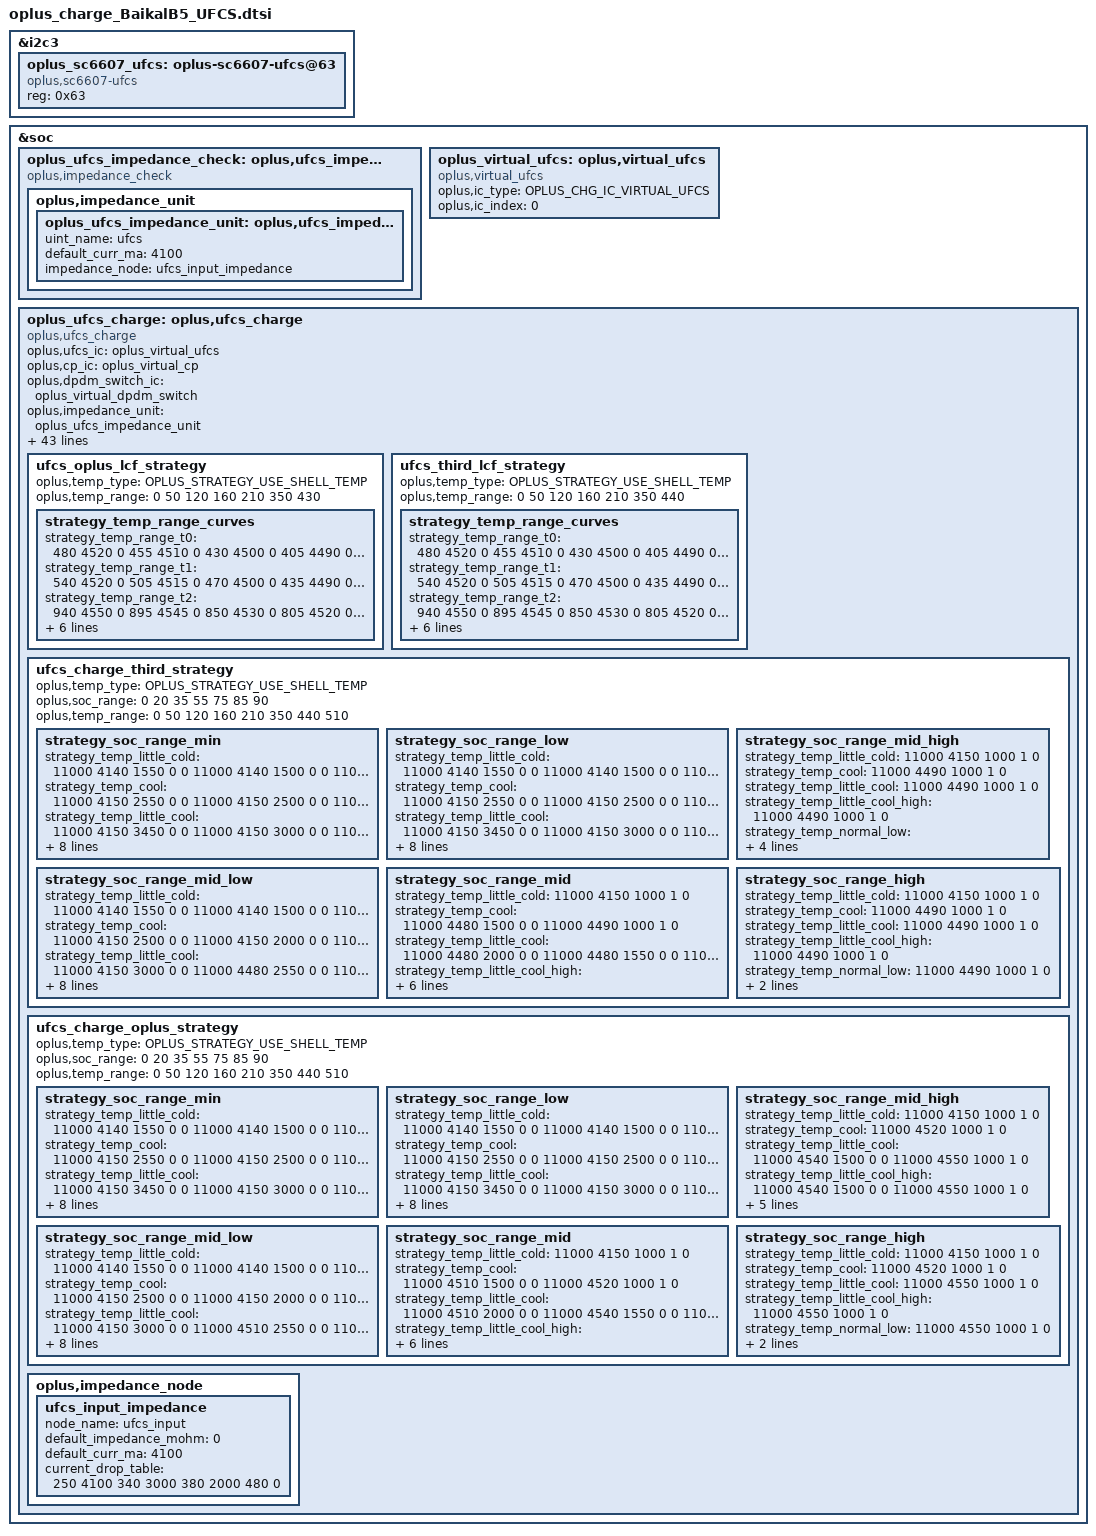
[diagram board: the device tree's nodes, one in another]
&i2c3 {
	oplus_sc6607_ufcs:oplus-sc6607-ufcs@63 {
		status = "okay";
		compatible = "oplus,sc6607-ufcs";
		reg = <0x63>;
	};
};

&soc {
	oplus_ufcs_impedance_check: oplus,ufcs_impedance_check {
		compatible = "oplus,impedance_check";
		oplus,impedance_unit {
			oplus_ufcs_impedance_unit: oplus,ufcs_impedance_unit {
				uint_name = "ufcs";
				default_curr_ma = <4100>;
				impedance_node = <&ufcs_input_impedance>;
			};
		};
	};

	oplus_virtual_ufcs: oplus,virtual_ufcs {
		compatible = "oplus,virtual_ufcs";

		oplus,ic_type = <OPLUS_CHG_IC_VIRTUAL_UFCS>;
		oplus,ic_index = <0>;
	};

	oplus_ufcs_charge: oplus,ufcs_charge {
		compatible = "oplus,ufcs_charge";
		oplus,ufcs_ic = <&oplus_virtual_ufcs>;
		oplus,cp_ic = <&oplus_virtual_cp>;
		oplus,dpdm_switch_ic = <&oplus_virtual_dpdm_switch>;

		oplus,impedance_unit = <&oplus_ufcs_impedance_unit>;

		oplus,plc_strategy-data = <&oplus_ufcs_step_strategy &cp_2t1_simple_strategy>;
		oplus,plc_strategy-names = "default", "third";

		oplus,target_vbus_mv = <11000>;
		oplus,curr_max_ma = <4100>;
		oplus,curr_table_type = <UFCS_CURR_CP_TABLE>;
		oplus,high_imp_compensation_setting_mv = <50>;
		oplus,ufcs_boot_time_retry = <10>;
		oplus,lift_vbus_use_cpvout;
		oplus,subboard_ntc_abnormal_current = <4000>;
		oplus,ufcs_need_reset_adapter;

		oplus,ufcs_warm_allow_vol = <4000>;
		oplus,ufcs_warm_allow_soc = <50>;
		oplus,ufcs_strategy_normal_current = <4000>;
		oplus,ufcs_over_high_or_low_current = <4000>;
		oplus,ufcs_timeout_third = <17562>;
		oplus,ufcs_timeout_oplus = <17562>;
		oplus,ufcs_ibat_over_third = <9400>;
		oplus,ufcs_ibat_over_oplus = <9600>;

		oplus,ufcs_full_cool_sw_vbat = <4520>;
		oplus,ufcs_full_normal_sw_vbat = <4550>;
		oplus,ufcs_full_normal_hw_vbat = <4560>;
		oplus,ufcs_full_ffc_vbat = <4500>;
		oplus,ufcs_full_warm_vbat = <4130>;
		oplus,ufcs_full_cool_sw_vbat_third = <4490>;
		oplus,ufcs_full_normal_sw_vbat_third= <4490>;
		oplus,ufcs_full_normal_hw_vbat_third = <4500>;

		oplus,ufcs_current_change_timeout = <100>;
		oplus,ufcs_strategy_batt_high_temp = <405 420 430 395 410 425>;
		oplus,ufcs_strategy_high_current = <5000 4000 3000 3000 4000 5000>;
		oplus,ufcs_little_cool_high_temp = <200>;
		oplus,curve_strategy_name = "pps_ufcs_curve_v2";
		oplus_spec,ufcs_high_soc = <90>;
		oplus,ufcs_charge_strategy_soc = <0 20 35 50 75 85 90>;
		oplus,ufcs_charge_strategy_temp = <0 50 120 160 350 440 530>;
        oplus,temperature_strategy_name = "cgcl";
        oplus,temperature_strategy_data = <OPLUS_STRATEGY_USE_SHELL_TEMP
                                                0   385 7300 1 0
                                                375 405 5000 2 0
                                                395 420 4000 3 1
                                                410 430 3500 4 2
                                                420 440 2000 4 3>;
		ufcs_oplus_lcf_strategy {
			oplus,temp_type = <OPLUS_STRATEGY_USE_SHELL_TEMP>;
			oplus,temp_range = <0 50 120 160 210 350 430>;

			strategy_temp_range_curves {
				strategy_temp_range_t0 =	<480 4520 0
								 455 4510 0
								 430 4500 0
								 405 4490 0
								 380 4480 1>;
				strategy_temp_range_t1 =	<540 4520 0
								 505 4515 0
								 470 4500 0
								 435 4490 0
								 400 4480 1>;
				strategy_temp_range_t2 =	<940 4550 0
								 895 4545 0
								 850 4530 0
								 805 4520 0
								 760 4510 1>;
				strategy_temp_range_t3 =	<940 4550 0
								 895 4545 0
								 850 4530 0
								 805 4520 0
								 760 4510 1>;
				strategy_temp_range_t4 =	<1780 4550 0
								 1730 4545 0
								 1630 4530 0
								 1530 4520 0
								 1380 4510 1>;
				strategy_temp_range_t5 =	<1910 4550 0
								 1860 4545 0
								 1760 4530 0
								 1660 4520 0
								 1510 4510 1>;
			};
		};

		ufcs_third_lcf_strategy {
			oplus,temp_type = <OPLUS_STRATEGY_USE_SHELL_TEMP>;
			oplus,temp_range = <0 50 120 160 210 350 440>;

			strategy_temp_range_curves {
				strategy_temp_range_t0 =	<480 4520 0
								 455 4510 0
								 430 4500 0
								 405 4490 0
								 380 4480 1>;
				strategy_temp_range_t1 =	<540 4520 0
								 505 4515 0
								 470 4500 0
								 435 4490 0
								 400 4480 1>;
				strategy_temp_range_t2 =	<940 4550 0
								 895 4545 0
								 850 4530 0
								 805 4520 0
								 760 4510 1>;
				strategy_temp_range_t3 =	<940 4550 0
								 895 4545 0
								 850 4530 0
								 805 4520 0
								 760 4510 1>;
				strategy_temp_range_t4 =	<1780 4550 0
								 1730 4545 0
								 1630 4530 0
								 1530 4520 0
								 1380 4510 1>;
				strategy_temp_range_t5 =	<1910 4550 0
								 1860 4545 0
								 1760 4530 0
								 1660 4520 0
								 1510 4510 1>;
			};
		};

		ufcs_charge_third_strategy {
			oplus,temp_type = <OPLUS_STRATEGY_USE_SHELL_TEMP>;
			oplus,soc_range = <0 20 35 55 75 85 90>;
			oplus,temp_range = <0 50 120 160 210 350 440 510>;

			strategy_soc_range_min {
				strategy_temp_little_cold =	<11000 4140 1550 0 0
                                    				11000 4140 1500 0 0
								11000 4150 1000 1 0>;
				strategy_temp_cool =		<11000 4150 2550 0 0
                                    				11000 4150 2500 0 0
                                    				11000 4150 2000 0 0
                                    				11000 4480 1550 0 0
								11000 4480 1500 0 0
								11000 4490 1000 1 0>;
				strategy_temp_little_cool =	<11000 4150 3450 0 0
                                    				11000 4150 3000 0 0
								11000 4480 2550 0 0
                                    				11000 4480 2500 0 0
								11000 4480 2000 0 0
								11000 4480 1550 0 0
								11000 4480 1500 0 0
								11000 4490 1000 1 0>;
				strategy_temp_little_cool_high =<11000 4150 3450 0 0
                                    				11000 4150 3000 0 0
								11000 4480 2550 0 0
                                    				11000 4480 2500 0 0
								11000 4480 2000 0 0
								11000 4480 1550 0 0
								11000 4480 1500 0 0
								11000 4490 1000 1 0>;
				strategy_temp_normal_low =	<11000 4150 4000 0 0
								11000 4150 3500 0 0
								11000 4230 3450 0 0
								11000 4230 3000 0 0
								11000 4480 2550 0 0
								11000 4480 2500 0 0
								11000 4480 2000 0 0
                                    				11000 4480 1550 0 0
								11000 4480 1500 0 0
								11000 4490 1000 1 0>;
				strategy_temp_normal_high =	<11000 4150 4000 0 0
								11000 4150 3500 0 0
								11000 4230 3450 0 0
								11000 4230 3000 0 0
								11000 4460 2550 0 0
								11000 4460 2500 0 0
								11000 4460 2000 0 0
                                    				11000 4460 1550 0 0
								11000 4460 1500 0 0
								11000 4470 1000 1 0>;
				strategy_temp_warm =		<11000 4120 1850 0 0
                                    				11000 4120 1500 0 0
								11000 4130 1000 1 0>;
			};
			strategy_soc_range_low {
				strategy_temp_little_cold =	<11000 4140 1550 0 0
                                    				11000 4140 1500 0 0
								11000 4150 1000 1 0>;
				strategy_temp_cool =		<11000 4150 2550 0 0
                                    				11000 4150 2500 0 0
                                    				11000 4150 2000 0 0
                                    				11000 4480 1550 0 0
								11000 4480 1500 0 0
								11000 4490 1000 1 0>;
				strategy_temp_little_cool =	<11000 4150 3450 0 0
                                    				11000 4150 3000 0 0
								11000 4480 2550 0 0
                                    				11000 4480 2500 0 0
								11000 4480 2000 0 0
								11000 4480 1550 0 0
								11000 4480 1500 0 0
								11000 4490 1000 1 0>;
				strategy_temp_little_cool_high =<11000 4150 3450 0 0
                                    				11000 4150 3000 0 0
								11000 4480 2550 0 0
                                    				11000 4480 2500 0 0
								11000 4480 2000 0 0
								11000 4480 1550 0 0
								11000 4480 1500 0 0
								11000 4490 1000 1 0>;
				strategy_temp_normal_low =	<11000 4150 4000 0 0
								11000 4150 3500 0 0
								11000 4230 3450 0 0
								11000 4230 3000 0 0
								11000 4480 2550 0 0
								11000 4480 2500 0 0
								11000 4480 2000 0 0
                                    				11000 4480 1550 0 0
								11000 4480 1500 0 0
								11000 4490 1000 1 0>;
				strategy_temp_normal_high =	<11000 4150 4000 0 0
								11000 4150 3500 0 0
								11000 4230 3450 0 0
								11000 4230 3000 0 0
								11000 4460 2550 0 0
								11000 4460 2500 0 0
								11000 4460 2000 0 0
                                    				11000 4460 1550 0 0
								11000 4460 1500 0 0
								11000 4470 1000 1 0>;
				strategy_temp_warm =		<11000 4120 1850 0 0
                                    				11000 4120 1500 0 0
								11000 4130 1000 1 0>;
			};
			strategy_soc_range_mid_low {
				strategy_temp_little_cold =	<11000 4140 1550 0 0
                                    				11000 4140 1500 0 0
								11000 4150 1000 1 0>;
				strategy_temp_cool =		<11000 4150 2500 0 0
                                    				11000 4150 2000 0 0
                                    				11000 4480 1550 0 0
								11000 4480 1500 0 0
								11000 4490 1000 1 0>;
				strategy_temp_little_cool =	<11000 4150 3000 0 0
								11000 4480 2550 0 0
                                   				11000 4480 2500 0 0
								11000 4480 2000 0 0
								11000 4480 1550 0 0
								11000 4480 1500 0 0
								11000 4490 1000 1 0>;
				strategy_temp_little_cool_high =<11000 4150 3000 0 0
								11000 4480 2550 0 0
                                    				11000 4480 2500 0 0
								11000 4480 2000 0 0
								11000 4480 1550 0 0
								11000 4480 1500 0 0
								11000 4490 1000 1 0>;
				strategy_temp_normal_low =	<11000 4150 4000 0 0
								11000 4150 3500 0 0
								11000 4230 3450 0 0
								11000 4230 3000 0 0
								11000 4480 2550 0 0
								11000 4480 2500 0 0
								11000 4480 2000 0 0
                                    				11000 4480 1550 0 0
								11000 4480 1500 0 0
								11000 4490 1000 1 0>;
				strategy_temp_normal_high =	<11000 4150 4000 0 0
								11000 4150 3500 0 0
								11000 4230 3450 0 0
								11000 4230 3000 0 0
								11000 4460 2550 0 0
								11000 4460 2500 0 0
								11000 4460 2000 0 0
                                    				11000 4460 1550 0 0
								11000 4460 1500 0 0
								11000 4470 1000 1 0>;
				strategy_temp_warm =		<11000 4120 1850 0 0
								11000 4120 1500 0 0
								11000 4130 1000 1 0>;
			};
			strategy_soc_range_mid {
				strategy_temp_little_cold =	<11000 4150 1000 1 0>;
				strategy_temp_cool =		<11000 4480 1500 0 0
								11000 4490 1000 1 0>;
				strategy_temp_little_cool =	<11000 4480 2000 0 0
								11000 4480 1550 0 0
								11000 4480 1500 0 0
								11000 4490 1000 1 0>;
				strategy_temp_little_cool_high =<11000 4480 2000 0 0
								11000 4480 1550 0 0
								11000 4480 1500 0 0
								11000 4490 1000 1 0>;
				strategy_temp_normal_low =	<11000 4480 2000 0 0
								11000 4480 1550 0 0
								11000 4480 1500 0 0
								11000 4490 1000 1 0>;
				strategy_temp_normal_high =	<11000 4460 2000 0 0
								11000 4460 1550 0 0
								11000 4460 1500 0 0
								11000 4470 1000 1 0>;
				strategy_temp_warm =		<11000 4130 1000 1 0>;
			};
			strategy_soc_range_mid_high {
				strategy_temp_little_cold =	<11000 4150 1000 1 0>;
				strategy_temp_cool =		<11000 4490 1000 1 0>;
				strategy_temp_little_cool =	<11000 4490 1000 1 0>;
				strategy_temp_little_cool_high =<11000 4490 1000 1 0>;
				strategy_temp_normal_low =	<11000 4480 1500 0 0
								11000 4490 1000 1 0>;
				strategy_temp_normal_high =	<11000 4460 1500 0 0
								11000 4470 1000 1 0>;
				strategy_temp_warm =		<11000 4130 1000 1 0>;
			};
			strategy_soc_range_high {
				strategy_temp_little_cold =	<11000 4150 1000 1 0>;
				strategy_temp_cool =		<11000 4490 1000 1 0>;
				strategy_temp_little_cool =	<11000 4490 1000 1 0>;
				strategy_temp_little_cool_high =<11000 4490 1000 1 0>;
				strategy_temp_normal_low =	<11000 4490 1000 1 0>;
				strategy_temp_normal_high =	<11000 4470 1000 1 0>;
				strategy_temp_warm =		<11000 4130 1000 1 0>;
			};
		};

		ufcs_charge_oplus_strategy {
			oplus,temp_type = <OPLUS_STRATEGY_USE_SHELL_TEMP>;
			oplus,soc_range = <0 20 35 55 75 85 90>;
			oplus,temp_range = <0 50 120 160 210 350 440 510>;

			strategy_soc_range_min {
				strategy_temp_little_cold =	<11000 4140 1550 0 0
                                    				11000 4140 1500 0 0
								11000 4150 1000 1 0>;
				strategy_temp_cool =		<11000 4150 2550 0 0
                                    				11000 4150 2500 0 0
                                    				11000 4150 2000 0 0
                                    				11000 4510 1550 0 0
								11000 4510 1500 0 0
								11000 4520 1000 1 0>;
				strategy_temp_little_cool =	<11000 4150 3450 0 0
                                    				11000 4150 3000 0 0
								11000 4510 2550 0 0
                                    				11000 4510 2500 0 0
								11000 4510 2000 0 0
								11000 4540 1550 0 0
								11000 4540 1500 0 0
								11000 4550 1000 1 0>;
				strategy_temp_little_cool_high =<11000 4150 3450 0 0
                                    				11000 4150 3000 0 0
								11000 4510 2550 0 0
                                    				11000 4510 2500 0 0
								11000 4510 2000 0 0
								11000 4540 1550 0 0
								11000 4540 1500 0 0
								11000 4550 1000 1 0>;
				strategy_temp_normal_low =	<11000 4150 4100 0 0
                                    				11000 4150 4000 0 0
								11000 4150 3500 0 0
								11000 4230 3450 0 0
								11000 4230 3000 0 0
								11000 4510 2550 0 0
								11000 4510 2500 0 0
								11000 4510 2000 0 0
                                    				11000 4540 1550 0 0
								11000 4540 1500 0 0
								11000 4550 1000 1 0>;
				strategy_temp_normal_high =	<11000 4150 4100 0 0
                                    				11000 4150 4000 0 0
								11000 4150 3500 0 0
								11000 4230 3450 0 0
								11000 4230 3000 0 0
								11000 4510 2550 0 0
								11000 4510 2500 0 0
								11000 4510 2000 0 0
                                    11000 4540 1550 0 0
								11000 4540 1500 0 0
								11000 4550 1000 1 0>;
				strategy_temp_warm =		<11000 4120 1850 0 0
                                    11000 4120 1500 0 0
								11000 4130 1000 1 0>;
			};
			strategy_soc_range_low {
				strategy_temp_little_cold =	<11000 4140 1550 0 0
                                    				11000 4140 1500 0 0
								11000 4150 1000 1 0>;
				strategy_temp_cool =		<11000 4150 2550 0 0
                                    				11000 4150 2500 0 0
                                    				11000 4150 2000 0 0
                                    				11000 4510 1550 0 0
								11000 4510 1500 0 0
								11000 4520 1000 1 0>;
				strategy_temp_little_cool =	<11000 4150 3450 0 0
                                    				11000 4150 3000 0 0
								11000 4510 2550 0 0
                                    				11000 4510 2500 0 0
								11000 4510 2000 0 0
								11000 4540 1550 0 0
								11000 4540 1500 0 0
								11000 4550 1000 1 0>;
				strategy_temp_little_cool_high =<11000 4150 3450 0 0
                                    				11000 4150 3000 0 0
								11000 4510 2550 0 0
                                    				11000 4510 2500 0 0
								11000 4510 2000 0 0
								11000 4540 1550 0 0
								11000 4540 1500 0 0
								11000 4550 1000 1 0>;
				strategy_temp_normal_low =	<11000 4150 4100 0 0
                                    				11000 4150 4000 0 0
								11000 4150 3500 0 0
								11000 4230 3450 0 0
								11000 4230 3000 0 0
								11000 4510 2550 0 0
								11000 4510 2500 0 0
								11000 4510 2000 0 0
                                    				11000 4540 1550 0 0
								11000 4540 1500 0 0
								11000 4550 1000 1 0>;
				strategy_temp_normal_high =	<11000 4150 4100 0 0
                                    				11000 4150 4000 0 0
								11000 4150 3500 0 0
								11000 4230 3450 0 0
								11000 4230 3000 0 0
								11000 4510 2550 0 0
								11000 4510 2500 0 0
								11000 4510 2000 0 0
                                    				11000 4540 1550 0 0
								11000 4540 1500 0 0
								11000 4550 1000 1 0>;
				strategy_temp_warm =		<11000 4120 1850 0 0
                                    				11000 4120 1500 0 0
								11000 4130 1000 1 0>;
			};
			strategy_soc_range_mid_low {
				strategy_temp_little_cold =	<11000 4140 1550 0 0
                                    				11000 4140 1500 0 0
								11000 4150 1000 1 0>;
				strategy_temp_cool =		<11000 4150 2500 0 0
                                    				11000 4150 2000 0 0
                                    				11000 4510 1550 0 0
								11000 4510 1500 0 0
								11000 4520 1000 1 0>;
				strategy_temp_little_cool =	<11000 4150 3000 0 0
                                    				11000 4510 2550 0 0
								11000 4510 2500 0 0
								11000 4510 2000 0 0
                                    				11000 4540 1550 0 0
								11000 4540 1500 0 0
								11000 4550 1000 1 0>;
				strategy_temp_little_cool_high =<11000 4150 3000 0 0
								11000 4510 2550 0 0
								11000 4510 2500 0 0
								11000 4510 2000 0 0
								11000 4540 1550 0 0
								11000 4540 1500 0 0
								11000 4550 1000 1 0>;
				strategy_temp_normal_low =	<11000 4150 4100 0 0
                                    				11000 4150 4000 0 0
								11000 4150 3500 0 0
								11000 4230 3450 0 0
								11000 4230 3000 0 0
								11000 4510 2550 0 0
								11000 4510 2500 0 0
								11000 4510 2000 0 0
                                    				11000 4540 1550 0 0
								11000 4540 1500 0 0
								11000 4550 1000 1 0>;
				strategy_temp_normal_high =	<11000 4150 4100 0 0
                                    				11000 4150 4000 0 0
								11000 4150 3500 0 0
								11000 4230 3450 0 0
								11000 4230 3000 0 0
								11000 4510 2550 0 0
								11000 4510 2500 0 0
								11000 4510 2000 0 0
                                    				11000 4540 1550 0 0
								11000 4540 1500 0 0
								11000 4550 1000 1 0>;
				strategy_temp_warm =		<11000 4120 1850 0 0
                                    				11000 4120 1500 0 0
								11000 4130 1000 1 0>;
			};
			strategy_soc_range_mid {
				strategy_temp_little_cold =	<11000 4150 1000 1 0>;
				strategy_temp_cool =		<11000 4510 1500 0 0
								11000 4520 1000 1 0>;
				strategy_temp_little_cool =	<11000 4510 2000 0 0
								11000 4540 1550 0 0
								11000 4540 1500 0 0
								11000 4550 1000 1 0>;
				strategy_temp_little_cool_high =<11000 4510 2000 0 0
								11000 4540 1550 0 0
								11000 4540 1500 0 0
								11000 4550 1000 1 0>;
				strategy_temp_normal_low =	<11000 4510 2500 0 0
								11000 4510 2000 0 0
								11000 4540 1550 0 0
								11000 4540 1500 0 0
								11000 4550 1000 1 0>;
				strategy_temp_normal_high =	<11000 4510 2500 0 0
								11000 4510 2000 0 0
								11000 4540 1550 0 0
								11000 4540 1500 0 0
								11000 4550 1000 1 0>;
				strategy_temp_warm =		<11000 4130 1000 1 0>;
			};
			strategy_soc_range_mid_high {
				strategy_temp_little_cold =	<11000 4150 1000 1 0>;
				strategy_temp_cool =		<11000 4520 1000 1 0>;
				strategy_temp_little_cool =	<11000 4540 1500 0 0
								11000 4550 1000 1 0>;
				strategy_temp_little_cool_high =<11000 4540 1500 0 0
								11000 4550 1000 1 0>;
				strategy_temp_normal_low =	<11000 4540 1500 0 0
								11000 4550 1000 1 0>;
				strategy_temp_normal_high =	<11000 4540 1500 0 0
								11000 4550 1000 1 0>;
				strategy_temp_warm =		<11000 4130 1000 1 0>;
			};
			strategy_soc_range_high {
				strategy_temp_little_cold =	<11000 4150 1000 1 0>;
				strategy_temp_cool =		<11000 4520 1000 1 0>;
				strategy_temp_little_cool =	<11000 4550 1000 1 0>;
				strategy_temp_little_cool_high =<11000 4550 1000 1 0>;
				strategy_temp_normal_low =	<11000 4550 1000 1 0>;
				strategy_temp_normal_high =	<11000 4550 1000 1 0>;
				strategy_temp_warm =		<11000 4130 1000 1 0>;
			};
		};


		oplus,impedance_node {
			ufcs_input_impedance: ufcs_input_impedance {
				node_name = "ufcs_input";
				default_impedance_mohm = <0>;
				default_curr_ma = <4100>;
				current_drop_table = <
					250  4100
					340  3000
					380  2000
					480 0
				>;
			};
		};
	};
};
